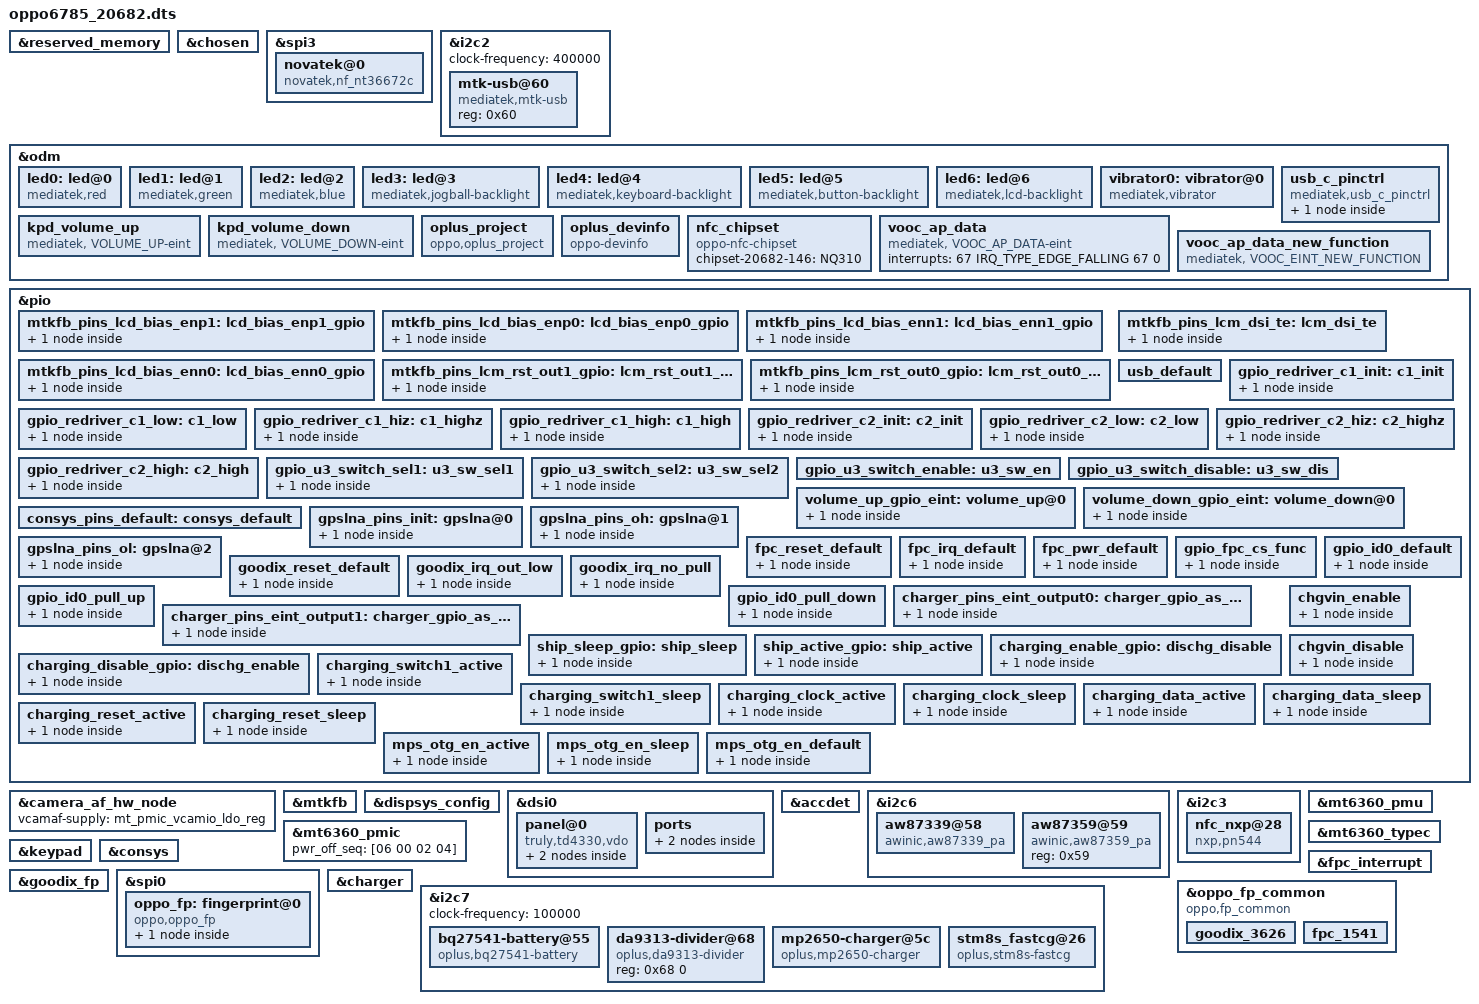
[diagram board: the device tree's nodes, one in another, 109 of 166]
/*
 * Mediatek's mt6873 SoC device tree source
 *
 * Copyright (C) 2016 MediaTek Inc.
 *
 * This program is free software; you can redistribute it and/or modify
 * it under the terms of the GNU General Public License version 2 as
 * published by the Free Software Foundation.
 *
 * This program is distributed in the hope that it will be useful,
 * but WITHOUT ANY WARRANTY; without even the implied warranty of
 * MERCHANTABILITY or FITNESS FOR A PARTICULAR PURPOSE.
 * See http://www.gnu.org/licenses/gpl-2.0.html for more details.
 */
/dts-v1/;
/plugin/;
#include <dt-bindings/interrupt-controller/irq.h>
#include <dt-bindings/interrupt-controller/arm-gic.h>
#include <dt-bindings/pinctrl/mt6873-pinfunc.h>

&reserved_memory {
};

/* chosen */
&chosen {

	atag,videolfb-fb_base_l = <0x7e605000>;
	atag,videolfb-fb_base_h = <0x0>;
	atag,videolfb-islcmfound = <1>;
	atag,videolfb-islcm_inited = <0>;
	atag,videolfb-fps= <6000>;
	atag,videolfb-vramSize= <0x1be0000>;
	atag,videolfb-lcmname=
		"nt35595_fhd_dsi_cmd_truly_nt50358_drv";
};
//#ifdef OPLUS_FEATURE_TP_BASIC
&spi3 {
	novatek@0 {
                compatible = "novatek,nf_nt36672c";
		reg = <0>;
		chip-name = "NT36672C_NF";
		status = "ok";

		spi-max-frequency = <15000000>; //4800000,9600000,15000000,19200000
		reset-gpio = <&pio 2 0>;
		interrupt-parent = <&pio>;
		interrupts = <0 IRQ_TYPE_EDGE_FALLING 0 0>; //1 IRQ_TYPE_EDGE_FALLING 1 0
		irq-gpio = <&pio 1 0>;
              //  lcd-reset-gpio = <&pio 44 0>;
		touchpanel,tx-rx-num = <16 36>;
		touchpanel,max-num-support = <10>;
		touchpanel,panel-coords = <1080 2400>;
		touchpanel,display-coords = <1080 2400>;
		touchpanel,touchmajor-limit = <0 54>;
//		tp_type = <6>;// type of tp_dev ,TP_JDI = 6;
//		tp_type = <7>;// type of tp_dev ,TP_TIANMA = 7;
		platform_support_project = <20682>;
		platform_support_project_dir = <20682>;
		platform_support_project_commandline = "nt36672c";
/*
		pinctrl-names ="active","suspend";
		pinctrl-0 = <&ts_int_active &ts_reset_active>;
		pinctrl-1 = <&ts_int_suspend &ts_reset_suspend>;
		pinctrl-names = "int_active","reset_active","int_suspend","reset_suspend";
		pinctrl-0 = <&ts_int_active>;
		pinctrl-1 = <&ts_reset_active>;
		pinctrl-2 = <&ts_int_suspend>;
		pinctrl-3 = <&ts_reset_suspend>;
*/
		incell_screen;
		fw_edge_limit_support;
		black_gesture_support;
		charger_pump_support;
		headset_pump_support;
		esd_handle_support;
		//spurious_fingerprint_support;
		//lcd_trigger_fp_check;
		black_gesture_test_support;
		noflash_support;
		smart_gesture_support;
		pressure_report_support;
		fw_update_app_support;
		game_switch_support;
		drlimit_remove_support;
		lcd_trigger_load_tp_fw_support;
		fw_update_in_probe_with_headfile;
		touchpanel,button-type = <4>;
	};
};

//#endif OPLUS_FEATURE_TP_BASIC
&i2c2 {
	clock-frequency = <400000>;

	mtk-usb@60 {
		compatible = "mediatek,mtk-usb";
		reg = <0x60>;
		status = "okay";
	};
};

&odm {
	led0:led@0 {
		compatible = "mediatek,red";
		led_mode = <0>;
		data = <1>;
		pwm_config = <0 0 0 0 0>;
	};
	led1:led@1 {
		compatible = "mediatek,green";
		led_mode = <0>;
		data = <1>;
		pwm_config = <0 0 0 0 0>;
	};
	led2:led@2 {
		compatible = "mediatek,blue";
		led_mode = <0>;
		data = <1>;
		pwm_config = <0 0 0 0 0>;
	};
	led3:led@3 {
		compatible = "mediatek,jogball-backlight";
		led_mode = <0>;
		data = <1>;
		pwm_config = <0 0 0 0 0>;
	};
	led4:led@4 {
		compatible = "mediatek,keyboard-backlight";
		led_mode = <0>;
		data = <1>;
		pwm_config = <0 0 0 0 0>;
	};
	led5:led@5 {
		compatible = "mediatek,button-backlight";
		led_mode = <0>;
		data = <1>;
		pwm_config = <0 0 0 0 0>;
	};
	led6:led@6 {
		compatible = "mediatek,lcd-backlight";
		//#ifndef ODM_HQ_EDIT
		//liyan@ODM.Multimedia.LCD  2019/08/27 modify for lcd-bl mode
		//led_mode = <5>;
		//#else
		led_mode = <4>;
		//#endif
		data = <1>;
		pwm_config = <0 1 0 0 0>;
	};
	vibrator0:vibrator@0 {
		compatible = "mediatek,vibrator";
		vib_timer = <30>;
		vib_limit = <0>;
		vib_vol= <11>;
	};
	usb_c_pinctrl:usb_c_pinctrl {
		compatible = "mediatek,usb_c_pinctrl";
	};
	kpd_volume_up:kpd_volume_up {
		compatible = "mediatek, VOLUME_UP-eint";
		interrupt-parent = <&pio>;
		interrupts = <59 IRQ_TYPE_EDGE_FALLING 59 0>;
		debounce = <32000>;
		status = "okay";
	};

	kpd_volume_down:kpd_volume_down {
		compatible = "mediatek, VOLUME_DOWN-eint";
		interrupt-parent = <&pio>;
		interrupts = <60 IRQ_TYPE_EDGE_FALLING 60 0>;
		debounce = <32000>;
		status = "okay";
	};

/*VNDOR_EDIT oppo project start */
	oplus_project:oplus_project {
		compatible = "oppo,oplus_project";
	};
	oplus_devinfo:oplus_devinfo {
		compatible = "oppo-devinfo";
	};

    //#ifdef OPLUS_FEATURE_NFC_CONSOFT
    nfc_chipset:nfc_chipset {
        compatible = "oppo-nfc-chipset";
        chipset-20682-146 = "NQ310";
    };
    //#endif /* OPLUS_FEATURE_NFC_CONSOFT */
};

/* DISPSYS GPIO standardization */

&pio {
	mtkfb_pins_lcd_bias_enp1: lcd_bias_enp1_gpio {
		pins_cmd_dat {
			pinmux = <PINMUX_GPIO23__FUNC_GPIO23>;
			slew-rate = <1>;
			output-high;
		};
	};

	mtkfb_pins_lcd_bias_enp0: lcd_bias_enp0_gpio {
		pins_cmd_dat {
			pinmux = <PINMUX_GPIO23__FUNC_GPIO23>;
			slew-rate = <1>;
			output-low;
		};
	};

	mtkfb_pins_lcd_bias_enn1: lcd_bias_enn1_gpio {
		pins_cmd_dat {
			pinmux = <PINMUX_GPIO202__FUNC_GPIO202>;
			slew-rate = <1>;
			output-high;
		};
	};

	mtkfb_pins_lcd_bias_enn0: lcd_bias_enn0_gpio {
		pins_cmd_dat {
			pinmux = <PINMUX_GPIO202__FUNC_GPIO202>;
			slew-rate = <1>;
			output-low;
		};
	};

	mtkfb_pins_lcm_rst_out1_gpio: lcm_rst_out1_gpio {
		pins_cmd_dat {
			pinmux = <PINMUX_GPIO44__FUNC_GPIO44>;
			slew-rate = <1>;
			output-high;
		};
	};

	mtkfb_pins_lcm_rst_out0_gpio: lcm_rst_out0_gpio {
		pins_cmd_dat {
			pinmux = <PINMUX_GPIO44__FUNC_GPIO44>;
			slew-rate = <1>;
			output-low;
		};
	};
	mtkfb_pins_lcm_dsi_te: lcm_dsi_te {
		pins_cmd_dat {
			pinmux = <PINMUX_GPIO43__FUNC_DSI_TE>;
		};
	};
};

&camera_af_hw_node {
	vcamaf-supply = <&mt_pmic_vcamio_ldo_reg>;
	status = "okay";
};

&mtkfb {
	pinctrl-names = "lcd_bias_enp1_gpio", "lcd_bias_enp0_gpio",
		"lcd_bias_enn1_gpio", "lcd_bias_enn0_gpio",
		"lcm_rst_out1_gpio", "lcm_rst_out0_gpio",
		"mode_te_te";
	pinctrl-0 = <&mtkfb_pins_lcd_bias_enp1>;
	pinctrl-1 = <&mtkfb_pins_lcd_bias_enp0>;
	pinctrl-2 = <&mtkfb_pins_lcd_bias_enn1>;
	pinctrl-3 = <&mtkfb_pins_lcd_bias_enn0>;
	pinctrl-4 = <&mtkfb_pins_lcm_rst_out1_gpio>;
	pinctrl-5 = <&mtkfb_pins_lcm_rst_out0_gpio>;
	pinctrl-6 = <&mtkfb_pins_lcm_dsi_te>;
	status = "okay";
};

&dispsys_config {
	pinctrl-names =
		"lcm_rst_out1_gpio", "lcm_rst_out0_gpio",
		"mode_te_te";
	pinctrl-0 = <&mtkfb_pins_lcm_rst_out1_gpio>;
	pinctrl-1 = <&mtkfb_pins_lcm_rst_out0_gpio>;
	pinctrl-2 = <&mtkfb_pins_lcm_dsi_te>;
	status = "okay";
};

&dsi0 {
	status = "okay";
	#address-cells = <1>;
	#size-cells = <0>;
	panel@0 {
		compatible = "truly,td4330,vdo";
		reg = <0>;
		pm-enable-gpios = <&pio 41 0>;
		reset-gpios = <&pio 42 0>;
		bias-gpios = <&pio 28 0>,
			<&pio 29 0>;
		pinctrl-names = "default";
		port {
			panel_in: endpoint {
				remote-endpoint = <&dsi_out>;
			};
		};
	};
	ports {
		port {
			dsi_out: endpoint {
				remote-endpoint = <&panel_in>;
			};
		};
	};
};

/* accdet start */
&accdet {
	/* accdet micbias voltage: 0x09:2.85v 0x08:2.8v 0x07,
	 * 2.7v;0x05,2.5v;0x02,1.9v
	 */
	accdet-mic-vol = <8>;
	/* accdet pwm_width, pwm_thresh, fall_delay, rise_delay
	 * debounce0, debounce1, debounce3, debounce4
	 * eint pwm_width, eint pwm_thresh
	 * eint deb(debounce0, debounce1, debounce2, debounce3), inv_debounce
	 */
	headset-mode-setting = <0x500 0x500 1 0x1f0
				0x800 0x800 0x20 0x44
				0x4 0x1
				0x5 0x3 0x3 0x5 0xe>;
	accdet-plugout-debounce = <1>;
	/*1:ACC mode, 2:low cost without in bias, 6:low cost with in bias*/
	accdet-mic-mode = <2>;
	/*0--MD_MAX--UP_MAX--DW_MAX*/
	headset-three-key-threshold = <0 80 220 400>;
	headset-three-key-threshold-CDD = <0 121 192 600>;
	/*0--MD_MAX--VOICE_MAX--UP_MAX--DW_MAX*/
	headset-four-key-threshold = <0 58 121 192 400>;

	/* select VTH to 2v and 500k, use internal resitance */
	eint_use_ext_res = <0>;
	status = "okay";
};
/* accdet end */

// wuhui@ODM.CM.Multimedia.Audio 2020/09/08 modified for aw87339 bringup
&i2c6 {
	aw87339@58 {
		compatible = "awinic,aw87339_pa";
		reg = <0x58>;
		reset-gpio = <&pio 24 0>;
		status = "okay";
	};
	// wuhui@ODM.CM.Multimedia.Audio 2020/09/08 add for aw87359 bringup
	aw87359@59 {
		compatible = "awinic,aw87359_pa";
		reg = <0x59>;
		status = "okay";
    };
};

//#ifdef OPLUS_FEATURE_NFC_BRINGUP
//LinJunBin@CONNECTIVITY.NFC.BASIC , 2020/09/19, add for : add NXP devices
&i2c3 {
       status = "okay";
       nfc_nxp@28 {
               compatible = "nxp,pn544";
               reg = <0x28>;
               nxp,pn544-irq = <&pio 5 0x0>;
               nxp,pn544-ven = <&pio 127 0x0>;
               nxp,pn544-fw-dwnld = <&pio 6 0x0>;
               interrupt-parent = <&pio>;
       };
};
//#endif /* OPLUS_FEATURE_NFC_BRINGUP */

/* liu.Yong@RM.CM.Charger 2020/07/28 modified for bring up charging begin*/
&mt6360_pmu {
	mt6360,intr_gpio_num = <16>; /* direct defined GPIO num */
	mt6360,intr_gpio = <&pio 16 0x0>;
};

&mt6360_pmic {
	pwr_off_seq = [06 00 02 04];
};

&mt6360_typec {
	mt6360pd,intr_gpio_num = <7>; /* direct defined GPIO num */
	mt6360pd,intr_gpio = <&pio 7 0x0>;
};

/* USB SWITCH GPIO start */
&pio {
	usb_default: usb_default {
	};

	gpio_redriver_c1_init: c1_init {
		pins_cmd_dat {
			pinmux = <PINMUX_GPIO40__FUNC_GPIO40>;
			slew-rate = <1>;
			output-low;
		};
	};

	gpio_redriver_c1_low: c1_low {
		pins_cmd_dat {
			pinmux = <PINMUX_GPIO40__FUNC_GPIO40>;
			slew-rate = <1>;
			output-low;
		};
	};

	gpio_redriver_c1_hiz: c1_highz {
		pins_cmd_dat {
			pinmux = <PINMUX_GPIO40__FUNC_GPIO40>;
			slew-rate= <0>;
			bias-disable;
		};
	};

	gpio_redriver_c1_high: c1_high {
		pins_cmd_dat {
			pinmux = <PINMUX_GPIO40__FUNC_GPIO40>;
			slew-rate = <1>;
			output-high;
		};
	};

	gpio_redriver_c2_init: c2_init {
		pins_cmd_dat {
			pinmux = <PINMUX_GPIO30__FUNC_GPIO30>;
			slew-rate = <1>;
			output-low;
		};
	};

	gpio_redriver_c2_low: c2_low {
		pins_cmd_dat {
			pinmux = <PINMUX_GPIO30__FUNC_GPIO30>;
			slew-rate = <1>;
			output-low;
		};
	};

	gpio_redriver_c2_hiz: c2_highz {
		pins_cmd_dat {
			pinmux = <PINMUX_GPIO30__FUNC_GPIO30>;
			slew-rate= <0>;
			bias-disable;
		};
	};

	gpio_redriver_c2_high: c2_high {
		pins_cmd_dat {
			pinmux = <PINMUX_GPIO30__FUNC_GPIO30>;
			slew-rate = <1>;
			output-high;
		};
	};

	gpio_u3_switch_sel1: u3_sw_sel1 {
		pins_cmd_dat {
			pinmux = <PINMUX_GPIO32__FUNC_GPIO32>;
			slew-rate = <1>;
			output-low;
		};
	};

	gpio_u3_switch_sel2: u3_sw_sel2 {
		pins_cmd_dat {
			pinmux = <PINMUX_GPIO32__FUNC_GPIO32>;
			slew-rate = <1>;
			output-high;
		};
	};

	gpio_u3_switch_enable: u3_sw_en {
	};

	gpio_u3_switch_disable: u3_sw_dis {
	};
};

&usb_c_pinctrl {
	pinctrl-names = "usb_default",
		"redrv_c1_init",
		"redrv_c1_low",
		"redrv_c1_hiz",
		"redrv_c1_high",
		"redrv_c2_init",
		"redrv_c2_low",
		"redrv_c2_hiz",
		"redrv_c2_high",
		"switch_sel1",
		"switch_sel2",
		"switch_enable",
		"switch_disable";

	pinctrl-0 = <&usb_default>;
	pinctrl-1 = <&gpio_redriver_c1_init>;
	pinctrl-2 = <&gpio_redriver_c1_low>;
	pinctrl-3 = <&gpio_redriver_c1_hiz>;
	pinctrl-4 = <&gpio_redriver_c1_high>;
	pinctrl-5 = <&gpio_redriver_c2_init>;
	pinctrl-6 = <&gpio_redriver_c2_low>;
	pinctrl-7 = <&gpio_redriver_c2_hiz>;
	pinctrl-8 = <&gpio_redriver_c2_high>;
	pinctrl-9 = <&gpio_u3_switch_sel1>;
	pinctrl-10 = <&gpio_u3_switch_sel2>;
	pinctrl-11 = <&gpio_u3_switch_enable>;
	pinctrl-12 = <&gpio_u3_switch_disable>;
	status = "okay";

	usb_switch-data {
		en_pin_num = <0>;
		en_pin_val = <0>;
		sel_pin_num = <32>;
		sel_pin_val = <1>;
		c1_pin_num = <31>;
		c1_pin_val = <2>;
		c2_pin_num = <30>;
		c2_pin_val = <1>;
	};
};
/* USB SWITCH GPIO end */
/* liu.Yong@RM.CM.Charger 2020/07/28 modified for bring up charging end*/

&keypad {
	keypad,volume-up	= <&pio 59 0x00>;
	keypad,volume-down	= <&pio 60 0x00>;
	pinctrl-names = "volume_up_as_int", "volume_down_as_int";
	pinctrl-0 = <&volume_up_gpio_eint>;
	pinctrl-1 = <&volume_down_gpio_eint>;
	status = "okay";
};
&pio {
	volume_up_gpio_eint:volume_up@0{
		pins_cmd_dat {
			pinmux = <PINMUX_GPIO59__FUNC_GPIO59>;
			slew-rate = <0>;  /*direction 0:in, 1:out*/
			bias-pull-up = <00>;
			input-enable;
		};
	};
	volume_down_gpio_eint:volume_down@0{
		pins_cmd_dat {
			pinmux = <PINMUX_GPIO60__FUNC_GPIO60>;
			slew-rate = <0>;  /*direction 0:in, 1:out*/
			bias-pull-up = <01>;
			input-enable;
		};
	};
};
/* CONSYS GPIO standardization */
&pio {
	consys_pins_default: consys_default {
	};
	gpslna_pins_init: gpslna@0 {
		pins_cmd_dat {
			pinmux = <PINMUX_GPIO155__FUNC_GPIO155>;
                        //#ifndef VENDOR_EDIT
                        //modify for: [GPS_LNA gpio's output direction is out]
                        /*
			slew-rate = <0>;
                        */
                        slew-rate = <1>;
                        //#endif /* VENDOR_EDIT */
			bias-disable;
			output-low;
		};
	};
	gpslna_pins_oh: gpslna@1 {
		pins_cmd_dat {
			pinmux = <PINMUX_GPIO155__FUNC_GPIO155>;
			slew-rate = <1>;
			output-high;
		};
	};
	gpslna_pins_ol: gpslna@2 {
		pins_cmd_dat {
			pinmux = <PINMUX_GPIO155__FUNC_GPIO155>;
			slew-rate = <1>;
			output-low;
		};
	};
};
&consys {
	pinctrl-names = "default", "gps_lna_state_init",
		"gps_lna_state_oh", "gps_lna_state_ol";
	pinctrl-0 = <&consys_pins_default>;
	pinctrl-1 = <&gpslna_pins_init>;
	pinctrl-2 = <&gpslna_pins_oh>;
	pinctrl-3 = <&gpslna_pins_ol>;
	status = "okay";
};
/* CONSYS end */

#include "mediatek/cust_mt6873_camera.dtsi"
#include "mediatek/cust_mt6873_touch_1080x2280.dtsi"
//#ifdef VENDOR_EDIT
/*the fpc device config start.*/
&pio {
	fpc_reset_default: fpc_reset_default {
		pins_cmd_dat {
			pinmux = <PINMUX_GPIO105__FUNC_GPIO105>;
			output-low;
		};
	};
	fpc_irq_default: fpc_irq_default {
		pins_cmd_dat {
			pinmux = <PINMUX_GPIO75__FUNC_GPIO75>;
			input;
			bias-pull-up;
		};
	};

	fpc_pwr_default: fpc_pwr_default {
		pins_cmd_dat {
			pinmux = <PINMUX_GPIO147__FUNC_GPIO147>;
			bias-disable;
			output-low;
		};
	};
	gpio_fpc_cs_func: gpio_fpc_cs_func {
		pins_cmd_dat {
			pinmux = <PINMUX_GPIO19__FUNC_GPIO19>;
			drive-strength = <3>;
		};
	};
};

&fpc_interrupt {
	pinctrl-names = "default", "fpc_cs_func";
	fpc,irq-gpio    = <&pio 75 0x00>;
	fpc,reset-gpio  = <&pio 105 0x00>;
//	fpc,vdd-en = <&pio 147 0x00>;
	fpc,gpio_cs = <&pio 19 0x00>;
	pinctrl-0 = <&fpc_reset_default>,<&fpc_irq_default>,<&fpc_pwr_default>;
	pinctrl-1 = <&gpio_fpc_cs_func>;
	status = "okay";
};
/*the fpc device config end.*/

/*-------------------the goodix device config start----------------------*/
&pio {
	goodix_reset_default: goodix_reset_default {
		pins_cmd_dat {
			pinmux = <PINMUX_GPIO105__FUNC_GPIO105>;
			output-low;
		};
	};
	goodix_irq_out_low: goodix_irq_out_low {
		pins_cmd_dat {
			pinmux = <PINMUX_GPIO75__FUNC_GPIO75>;
			input;
			output-low;
		};
	};
	goodix_irq_no_pull: goodix_irq_no_pull {
		pins_cmd_dat {
			pinmux = <PINMUX_GPIO75__FUNC_GPIO75>;
			bias-disable;
		};
	};
};

&goodix_fp {
	pinctrl-names = "goodix_reset_default", "goodix_irq_out_low", "goodix_irq_no_pull";
	pinctrl-0 = <&goodix_reset_default>;
	pinctrl-1 = <&goodix_irq_out_low>;
	pinctrl-2 = <&goodix_irq_no_pull>;
	interrupt-parent = <&pio>;
	interrupts = <75 0>;
	goodix,gpio_irq = <&pio 75 0x00>;
	goodix,gpio_reset = <&pio 105 0x00>;
	spi-max-frequency = <8000000>;
	status = "okay";
};
/*-------------------the goodix device config end----------------------*/

&spi0 {
    #address-cells = <1>;
    #size-cells = <0>;
    status = "okay";
    oppo_fp: fingerprint@0 {
        compatible = "oppo,oppo_fp";
        reg = <0>;
        spi-max-frequency = <8000000>;
        spi-id = <0>;
        spi-irq = <75>;
        spi-reg = <11010000>;
        //vfp-supply = <&mt_pmic_vfp_ldo_reg>;
        status = "okay";
        fpc,pw_en = <&pio 147 0x00>;
        power_source_1 {
             power-mode = <2>;
             power-name = "fpc,pw_en";
             poweron-level = "0";
             delay-time = <0>;
         };
    };
};

/*the finger_id config to project dts.*/
&pio{
	gpio_id0_default: gpio_id0_default {
		pins_cmd_dat {
			pinmux = <PINMUX_GPIO106__FUNC_GPIO106>;
			bias-pull-up;
		};
	};
	gpio_id0_pull_up: gpio_id0_pull_up {
		pins_cmd_dat {
			pinmux = <PINMUX_GPIO106__FUNC_GPIO106>;
			bias-pull-up;
		};
	};
	gpio_id0_pull_down: gpio_id0_pull_down {
		pins_cmd_dat {
			pinmux = <PINMUX_GPIO106__FUNC_GPIO106>;
			input;
			bias-pull-down ;
		};
	};
};

&oppo_fp_common {
	compatible = "oppo,fp_common"; //Manufacture, and Model
	oppo,fp_gpio_num = <1>;
	oppo,fp_gpio_0 = <&pio 106 0x00>;
	pinctrl-names = "default", "gpio_id0_pull_up", "gpio_id0_pull_down";
	pinctrl-0 = <&gpio_id0_default>;
	pinctrl-1 = <&gpio_id0_pull_up>;
	pinctrl-2 = <&gpio_id0_pull_down>;
	goodix_3626 {
		oppo,fp-id = <1>; /* fp id mapping table */
		vendor-chip = <16>; /* please refer to the struct fp_vendor_t in oppo_fp_commmon.n */
		eng-menu = "-1,-1"; /* represents SNR, inclination test item in engineer menu, and 0/1 means off/on */
		chip-name = "G_3626";  /* /proc/fp_id, will be displayed in engineer menu  */
	};
	fpc_1541 {
		oppo,fp-id = <0>; /* fp id mapping table */
		vendor-chip = <17>; /* please refer to the struct fp_vendor_t in oppo_fp_commmon.n */
		eng-menu = "-1,-1"; /* represents SNR, inclination test item in engineer menu, and 0/1 means off/on */
		chip-name = "F_1541";  /* /proc/fp_id, will be displayed in engineer menu  */
	};
};
//#endif /* VENDOR_EDIT */

/* liu.Yong@RM.CM.Charger 2020/07/28 modified for bring up charging */
&odm {
	vooc_ap_data:vooc_ap_data {
		compatible = "mediatek, VOOC_AP_DATA-eint";
		interrupts = <67 IRQ_TYPE_EDGE_FALLING 67 0>;
	};
	vooc_ap_data_new_function:vooc_ap_data_new_function {
		compatible = "mediatek, VOOC_EINT_NEW_FUNCTION";
	};
};

&charger {
	pinctrl-names = "charger_gpio_as_output_low", "charger_gpio_as_output_high", "ship_sleep", "ship_active", "dischg_disable", "dischg_enable", "chgvin_enable", "chgvin_disable";
	pinctrl-0 = <&charger_pins_eint_output0>;
	pinctrl-1 = <&charger_pins_eint_output1>;
	pinctrl-2 = <&ship_sleep_gpio>;
	pinctrl-3 = <&ship_active_gpio>;
	pinctrl-4 = <&charging_enable_gpio>;
	pinctrl-5 = <&charging_disable_gpio>;
	//pinctrl-5 = <&shortc_active_gpio>;
	pinctrl-6 = <&chgvin_enable>;
	pinctrl-7 = <&chgvin_disable>;
	qcom,hv_flashled_support;
	//for oppo chg framework:
	qcom,chargerid_support;
	qcom,input_current_charger_ma = <2200>;
	qcom,pd_input_current_charger_ma = <2000>;
	qcom,qc_input_current_charger_ma = <2000>;
	qcom,input_current_usb_ma = <500>;
	qcom,input_current_cdp_ma = <1500>;
	qcom,input_current_led_ma = <1200>;
	qcom,input_current_led_ma_forcmcc = <500>;
	qcom,input_current_camera_ma = <1200>;
	qcom,input_current_calling_ma = <1500>;
	qcom,input_current_led_ma_high = <500>;
	qcom,input_current_led_ma_limit_high = <1200>;
	qcom,input_current_led_ma_warm = <1500>;
	qcom,input_current_led_ma_normal = <2000>;

	qcom,led_warm_bat_decidegc = <350>;
	qcom,led_limit_high_bat_decidegc = <370>;

	qcom,input_current_vooc_led_ma_high = <1200>;
	qcom,input_current_vooc_led_ma_warm = <1800>;
	qcom,input_current_vooc_led_ma_normal = <3600>;
	qcom,input_current_vooc_ma_normal = <3600>;
	qcom,vooc_temp_bat_normal_decidegc = <350>;
	qcom,input_current_vooc_ma_warm = <3200>;
	qcom,vooc_temp_bat_warm_decidegc = <370>;
	qcom,input_current_vooc_ma_high = <2200>;
	qcom,led_high_bat_decidegc = <440>;
	qcom,vooc_temp_bat_hot_decidegc = <440>;

	qcom,charger_current_vooc_ma_normal = <1800>;

	qcom,overtemp_bat_decidegc = <350>;
	qcom,iterm_disabled = <0>;
	sw_full_count = <25>;
	qcom,iterm_ma = <300>;
	qcom,recharge-mv = <115>;

	qcom,batt_capacity_mah = <5000>; /*typical capacity*/
	//qcom,batt_capacity_mah = <3900>; /*rated capacity*/

	qcom,removed_bat_decidegc = <190>;  /* < -19C */

	qcom,cold_bat_decidegc = <20>;  /* -3C ~ 0C */
	qcom,temp_cold_vfloat_mv = <3980>;
	qcom,temp_cold_fastchg_current_ma = <360>;

	qcom,little_cold_bat_decidegc = <0>;	/* 0C ~ 5C */
	qcom,temp_little_cold_vfloat_mv = <4435>;
	qcom,temp_little_cold_fastchg_current_ma_high = <2200>;
	qcom,temp_little_cold_fastchg_current_ma_low = <1400>;
	qcom,temp_little_cold_fastchg_current_ma = <1200>;
	qcom,pd_temp_little_cold_fastchg_current_ma_high = <2000>;
	qcom,pd_temp_little_cold_fastchg_current_ma_low = <1400>;
	qcom,qc_temp_little_cold_fastchg_current_ma_high = <2000>;
	qcom,qc_temp_little_cold_fastchg_current_ma_low = <1400>;

	qcom,cool_bat_decidegc = <50>;	/* 5C ~ 12C */
	qcom,temp_cool_vfloat_mv = <4435>;
	qcom,temp_cool_fastchg_current_ma_high = <2200>;
	qcom,temp_cool_fastchg_current_ma_low = <1100>;
	qcom,pd_temp_cool_fastchg_current_ma_high = <2000>;
	qcom,qc_temp_cool_fastchg_current_ma_high = <2000>;
	qcom,qc_temp_cool_fastchg_current_ma_low = <2000>;

	qcom,little_cool_bat_decidegc = <120>;	/* 12C ~ 16C */
	qcom,temp_little_cool_vfloat_mv = <4435>;
	qcom,temp_little_cool_fastchg_current_ma = <2200>;
	qcom,pd_temp_little_cool_fastchg_current_ma = <2000>;
	qcom,qc_temp_little_cool_fastchg_current_ma = <2000>;

	qcom,normal_bat_decidegc = <160>;	/* 16C ~ 45C */
	qcom,temp_normal_fastchg_current_ma = <2200>;
	qcom,temp_normal_vfloat_mv = <4435>;
	qcom,pd_temp_normal_fastchg_current_ma = <2000>;
	qcom,qc_temp_normal_fastchg_current_ma = <2000>;

	qcom,warm_bat_decidegc = <450>;		/* 45C ~ 53C */ /*8pin Bat Vooc project need add 3 degree C*/

	qcom,temp_warm_vfloat_mv = <4150>;
	qcom,temp_warm_fastchg_current_ma = <1500>;
	qcom,pd_temp_warm_fastchg_current_ma = <600>;
	qcom,qc_temp_warm_fastchg_current_ma = <600>;
	qcom,temp_warm_fastchg_current_ma_led_on = <250>;

	qcom,hot_bat_decidegc = <530>;  /* > 53C */

	qcom,non_standard_vfloat_mv = <3980>;
	qcom,non_standard_fastchg_current_ma = <512>;

	qcom,short_c_bat_cv_mv = <4330>;
	qcom,short_c_bat_vfloat_mv = <3800>;
	qcom,short_c_bat_fastchg_current_ma = <512>;
	qcom,short_c_bat_vfloat_sw_limit = <3750>;

	qcom,cold_vfloat_sw_limit = <3930>;
	qcom,little_cold_vfloat_sw_limit = <4385>;
	qcom,cool_vfloat_sw_limit = <4385>;
	qcom,little_cool_vfloat_sw_limit = <4385>;
	qcom,normal_vfloat_sw_limit = <4385>;
	qcom,warm_vfloat_sw_limit = <4080>;
	qcom,non_standard_vfloat_sw_limit = <3930>;

	qcom,max_chg_time_sec = <67360>;
	qcom,charger_hv_thr = <5800>;
	qcom,charger_lv_thr = <3400>;
	qcom,vbatt_full_thr = <4400>;
	qcom,vbatt_hv_thr = <4550>;

	qcom,vfloat_step_mv = <16>;
	qcom,non_standard_vfloat_over_sw_limit = <3980>;
	qcom,cold_vfloat_over_sw_limit = <3980>;
	qcom,little_cold_vfloat_over_sw_limit = <4440>;
	qcom,cool_vfloat_over_sw_limit = <4440>;
	qcom,little_cool_vfloat_over_sw_limit = <4440>;
	qcom,normal_vfloat_over_sw_limit = <4440>;
	qcom,warm_vfloat_over_sw_limit = <4130>;

	qcom,vbatt_power_off = <3300>;
	qcom,vbatt_soc_1 = <3410>;
	qcom,vooc_project = <1>;
	qcom,vbatt_num = <1>;
	qcom,new_ui_warning_support;
	qcom,ffc_support;
	qcom,dual_ffc;
	recharge_after_full;

	qcom,normal_vterm_hw_inc = <150>;
	qcom,non_normal_vterm_hw_inc = <10>;

	qcom,ff1_normal_fastchg_ma = <1500>;
	qcom,ff1_warm_fastchg_ma = <1500>;
	qcom,ffc2_normal_fastchg_ma = <1200>;/*16C~35c*/
	qcom,ffc2_temp_warm_decidegc = <350>;
	qcom,ffc2_warm_fastchg_ma = <1250>;/*35C~40c*/
	qcom,ffc2_temp_high_decidegc = <400>;
	qcom,ffc2_temp_low_decidegc = <120>;
	qcom,ff1_exit_step_ma = <488>;
	qcom,ff1_warm_exit_step_ma = <418>;
	qcom,ffc2_exit_step_ma = <180>;
	qcom,ffc2_warm_exit_step_ma = <170>;

	qcom,ffc_normal_vfloat_sw_limit = <4475>;
	qcom,ffc_temp_normal_vfloat_mv = <4500>;
	qcom,ffc_normal_vfloat_over_sw_limit = <4500>;
	qcom,ffc_warm_vfloat_sw_limit = <4450>;
	qcom,ffc_temp_warm_vfloat_mv = <4500>;
	qcom,ffc_warm_vfloat_over_sw_limit = <4500>;

	/*hongzhenglong@ODM.HQ.BSP.CHG 2020/06/08 modify for thershold current in 20682*/
	qcom,ffc2_normal_vfloat_sw_limit = <4445>;
	qcom,ffc2_temp_normal_vfloat_mv = <4500>;
	qcom,ffc2_normal_vfloat_over_sw_limit = <4500>;
	qcom,ffc2_warm_vfloat_sw_limit = <4440>;
	qcom,ffc2_temp_warm_vfloat_mv = <4500>;
	qcom,ffc2_warm_vfloat_over_sw_limit = <4500>;

	qcom,default_iterm_ma = <300>;
	qcom,default_temp_normal_fastchg_current_ma = <2200>;
	qcom,default_normal_vfloat_sw_limit = <4385>;
	qcom,default_temp_normal_vfloat_mv = <4435>;
	qcom,default_normal_vfloat_over_sw_limit = <4440>;
	qcom,default_temp_little_cool_fastchg_current_ma = <1100>;
	qcom,default_little_cool_vfloat_sw_limit = <4385>;
	qcom,default_temp_little_cool_vfloat_mv = <4435>;
	qcom,default_little_cool_vfloat_over_sw_limit = <4445>;
	//qcom,suspend_after_full;
	qcom,check_batt_full_by_sw;
	qcom,external_gauge;
	qcom,chg_ctrl_by_calling;
	qcom,chg_ctrl_by_lcd;
	qcom,chg_ctrl_by_vooc;
	qcom,chg_ctrl_by_camera;
	qcom,sw_vfloat_over_protect_enable;

	//for PD9V or QC9V
	qcom,vbatt_pdqc_to_5v_thr = <4100>;
	qcom,vbatt_pdqc_to_9v_thr = <4000>;

	//GPIO config:
	qcom,chargerid_switch-gpio = <&pio 195 0x00>;
	qcom,ship-gpio = <&pio 26 0x00>;
	qcom,dischg-gpio = <&pio 13 0x00>;
	//qcom,shortc-gpio = <&pio 148 0x00>;
	qcom,chgvin = <&pio 127 0x00>;
	io-channels = <&auxadc 5>;
	io-channel-names = "chargerID-channel";
};

&i2c7 {
	status = "okay";
	clock-frequency = <100000>;
	bq27541-battery@55 {
		status = "okay";
		compatible = "oplus,bq27541-battery";
		reg = <0x55 0>;
		qcom,modify-soc-smooth;
	};

	da9313-divider@68 {
		status = "okay";
		compatible = "oplus,da9313-divider";
		reg = <0x68 0>;
	};

	mp2650-charger@5c {
		status = "okay";
		compatible = "oplus,mp2650-charger";
		reg = <0x5c 0>;

		qcom,mps_otg_en-gpio = <&pio 151 0x00>;
		pinctrl-names = "mps_otg_en_active", "mps_otg_en_sleep", "mps_otg_en_default";
		pinctrl-0 = <&mps_otg_en_active>;
		pinctrl-1 = <&mps_otg_en_sleep>;
		pinctrl-2 = <&mps_otg_en_default>;
	};

	stm8s_fastcg@26{
		status = "okay";
		compatible = "oplus,stm8s-fastcg";
		reg = <0x26 0>;
		qcom,vooc-low-temp = <50>;
		qcom,oplus_batt_4400mv;
		qcom,vooc_fw_update_newmethod;
		qcom,vooc-fw-type = <7>;
		qcom,vooc-high-temp = <430>;
		qcom,vooc-low-soc = <1>;
		qcom,vooc-high-soc = <90>;

		qcom,vooc_multistep_adjust_current_support;
		qcom,vooc_multistep_initial_batt_temp = <1000>;
		qcom,vooc_strategy_normal_current = <0x06>;

		qcom,vooc_batt_over_high_temp = <440>;
		qcom,vooc_batt_over_low_temp = <50>;
		qcom,vooc_over_high_or_low_current = <0x0>;
		qcom,vooc_strategy1_batt_high_temp0 = <410>;
		qcom,vooc_strategy1_batt_high_temp1 = <425>;
		qcom,vooc_strategy1_batt_high_temp2 = <435>;
		qcom,vooc_strategy1_batt_low_temp2 = <430>;
		qcom,vooc_strategy1_batt_low_temp1 = <410>;
		qcom,vooc_strategy1_batt_low_temp0 = <390>;

		qcom,vooc_strategy1_high_current0 = <0x04>;//4A
		qcom,vooc_strategy1_high_current1 = <0x03>;//3A
		qcom,vooc_strategy1_high_current2 = <0x02>;//2A
		qcom,vooc_strategy1_low_current2 = <0x03>;//3A
		qcom,vooc_strategy1_low_current1 = <0x05>;//5A
		qcom,vooc_strategy1_low_current0 = <0x06>;//6A

		qcom,vooc_strategy2_batt_up_temp1 = <370>;
		qcom,vooc_strategy2_batt_up_down_temp2 = <380>;
		qcom,vooc_strategy2_batt_up_temp3 = <390>;
		qcom,vooc_strategy2_batt_up_down_temp4 = <395>;
		qcom,vooc_strategy2_batt_up_temp5 = <400>;
		qcom,vooc_strategy2_batt_up_temp6 = <415>;
		qcom,vooc_strategy2_high0_current = <0x06>;
		qcom,vooc_strategy2_high1_current = <0x06>;
		qcom,vooc_strategy2_high2_current = <0x06>;
		qcom,vooc_strategy2_high3_current = <0x06>;

		pinctrl-names = "switch1_act_switch2_act", "switch1_sleep_switch2_sleep",
						"switch1_act_switch3_act", "switch1_sleep_switch3_sleep",
						"switch1_act_switch2_sleep", "switch1_sleep_switch2_act",
						"clock_active","clock_sleep",
						"data_active","data_sleep",
						"reset_active","reset_sleep";
		pinctrl-0 = <&charging_switch1_active>;
		pinctrl-1 = <&charging_switch1_sleep>;
		pinctrl-2 = <&charging_switch1_active>;
		pinctrl-3 = <&charging_switch1_sleep>;
		pinctrl-4 = <&charging_switch1_active>;
		pinctrl-5 = <&charging_switch1_sleep>;
		pinctrl-6 = <&charging_clock_active>;
		pinctrl-7 = <&charging_clock_sleep>;
		pinctrl-8 = <&charging_data_active>;
		pinctrl-9 = <&charging_data_sleep>;
		pinctrl-10 = <&charging_reset_active>;
		pinctrl-11 = <&charging_reset_sleep>;

		qcom,charging_switch1-gpio 		= <&pio 34 0x00>;
		//qcom,charging_switch2-gpio 		= <&tlmm 34 0x00>;
		//qcom,charging_switch3-gpio 		= <&tlmm 34 0x00>;

		qcom,charging_reset-gpio 			= <&pio 14 0x00>;
		qcom,charging_clock-gpio 			= <&pio 68 0x00>;
		qcom,charging_data-gpio 			= <&pio 67 0x00>;
	};
};

&pio {
	//charger_pins_default: eint0default {
	//};
	charger_pins_eint_output0: charger_gpio_as_output_low {
		pins_cmd_dat {
			pinmux = <PINMUX_GPIO195__FUNC_GPIO195>;
			slew-rate = <1>;
			output-low;
		};
	};
	charger_pins_eint_output1: charger_gpio_as_output_high {
		pins_cmd_dat {
			pinmux = <PINMUX_GPIO195__FUNC_GPIO195>;
			slew-rate = <1>;
			output-high;
		};
	};

	ship_sleep_gpio: ship_sleep {
		pins_cmd_dat {
			pinmux = <PINMUX_GPIO26__FUNC_GPIO26>;
			slew-rate = <1>;
			output-low;
		};
	};
	ship_active_gpio: ship_active {
		pins_cmd_dat {
			pinmux = <PINMUX_GPIO26__FUNC_GPIO26>;
			slew-rate = <1>;
			output-high;
		};
	};
	
	charging_enable_gpio: dischg_disable {
		pins_cmd_dat {
			pinmux = <PINMUX_GPIO13__FUNC_GPIO13>;
			slew-rate = <1>;
			output-low;
		};
	};
	charging_disable_gpio: dischg_enable {
		pins_cmd_dat {
			pinmux = <PINMUX_GPIO13__FUNC_GPIO13>;
			slew-rate = <1>;
			output-high;
		};
	};
	
	chgvin_enable: chgvin_enable {
		pins_cmd_dat {
			pinmux = <PINMUX_GPIO127__FUNC_GPIO127>;
			slew-rate = <1>;//0:input direction 1:output direction
			bias-pull-up = <00>;
			output-low;
		};
	};
	chgvin_disable: chgvin_disable {
		pins_cmd_dat {
			pinmux = <PINMUX_GPIO127__FUNC_GPIO127>;
			slew-rate = <1>;
			bias-pull-down = <00>;
			output-high;
		};
	};

	//shortc_active_gpio: shortc_active {
	//	pins_cmd_dat {
	//		pinmux = <PINMUX_GPIO148__FUNC_GPIO148>;
	//		input-enable;
	//		slew-rate = <0>;
	//		bias-pull-up;
	//	};
	//};
};

&pio {
	charging_switch1_active: charging_switch1_active {
		pins_cmd_dat {
			pinmux = <PINMUX_GPIO34__FUNC_GPIO34>;
			slew-rate = <1>;
			output-high;
		};
	};
	charging_switch1_sleep: charging_switch1_sleep {
		pins_cmd_dat {
			pinmux = <PINMUX_GPIO34__FUNC_GPIO34>;
			slew-rate = <1>;
			output-low;
		};
	};
	charging_clock_active: charging_clock_active {
		pins_cmd_dat {
			pinmux = <PINMUX_GPIO68__FUNC_GPIO68>;
			slew-rate = <0>;
			bias-pull-up = <00>;
		};
	};
	charging_clock_sleep: charging_clock_sleep {
		pins_cmd_dat {
			pinmux = <PINMUX_GPIO68__FUNC_GPIO68>;
			slew-rate = <0>;
			bias-pull-down = <00>;
		};
	};
	charging_data_active: charging_data_active {
		pins_cmd_dat {
			pinmux = <PINMUX_GPIO67__FUNC_GPIO67>;
			slew-rate = <0>;
			bias-pull-up = <00>;
		};
	};
	charging_data_sleep: charging_data_sleep {
		pins_cmd_dat {
			pinmux = <PINMUX_GPIO67__FUNC_GPIO67>;
			slew-rate = <0>;
			bias-pull-down = <00>;
		};
	};
	charging_reset_active: charging_reset_active {
		pins_cmd_dat {
			pinmux = <PINMUX_GPIO14__FUNC_GPIO14>;
			slew-rate = <1>;
			output-high;
		};
	};
	charging_reset_sleep: charging_reset_sleep {
		pins_cmd_dat {
			pinmux = <PINMUX_GPIO14__FUNC_GPIO14>;
			slew-rate = <1>;
			output-low;
		};
	};
};

&pio {
	mps_otg_en_active: mps_otg_en_active {
		pins_cmd_dat {
			pinmux = <PINMUX_GPIO151__FUNC_GPIO151>;
                        slew-rate = <1>;
                        output-high;
		};
	};

	mps_otg_en_sleep: mps_otg_en_sleep {
		pins_cmd_dat {
			pinmux = <PINMUX_GPIO151__FUNC_GPIO151>;
			slew-rate = <1>;
			output-low;
		};
	};

	mps_otg_en_default: mps_otg_en_default {
		pins_cmd_dat {
			pinmux = <PINMUX_GPIO151__FUNC_GPIO151>;
			slew-rate = <1>;
			output-low;
		};
	};
};


#include <oppo6785_20682/cust.dtsi>
/*End of this file, DO NOT ADD ANYTHING HERE*/
